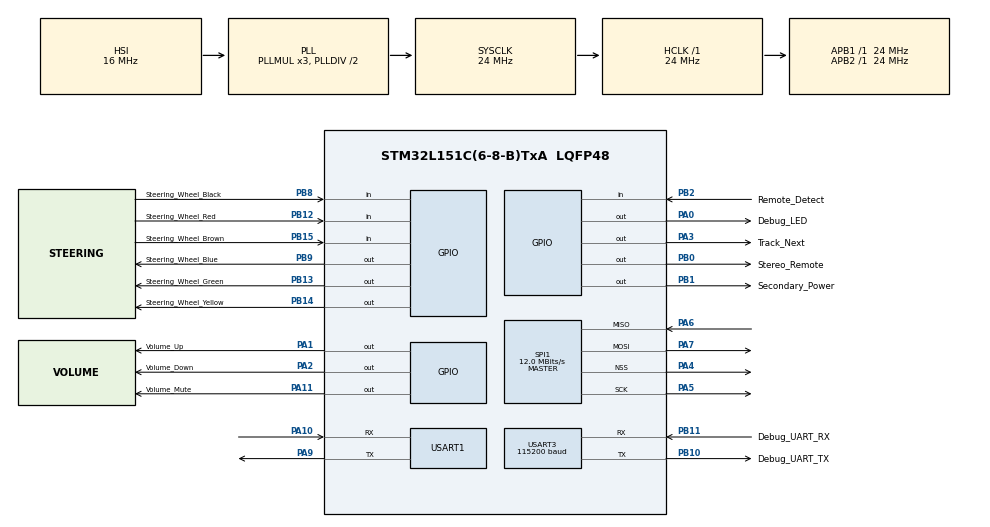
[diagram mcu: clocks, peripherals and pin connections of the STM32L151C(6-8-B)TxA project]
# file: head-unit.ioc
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Mcu.Family=STM32L1
Mcu.Name=STM32L151C(6-8-B)TxA
Mcu.Package=LQFP48
NVIC.PriorityGroup=NVIC_PRIORITYGROUP_4
PA0-WKUP1.GPIO_Label=Debug_LED
PA0-WKUP1.Signal=GPIO_Output
PA1.GPIO_Label=Volume_Up
PA1.Signal=GPIO_Output
PA10.Mode=Asynchronous
PA10.Signal=USART1_RX
PA11.GPIO_Label=Volume_Mute
PA11.Signal=GPIO_Output
PA13.GPIO_Label=Programmer_DIO
PA13.Signal=SYS_JTMS-SWDIO
PA14.GPIO_Label=Programmer_CLK
PA14.Signal=SYS_JTCK-SWCLK
PA2.GPIO_Label=Volume_Down
PA2.Signal=GPIO_Output
PA3.GPIO_Label=Track_Next
PA3.Signal=GPIO_Output
PA4.Mode=NSS_Signal_Hard_Output
PA4.Signal=SPI1_NSS
PA5.Mode=Full_Duplex_Master
PA5.Signal=SPI1_SCK
PA6.Mode=Full_Duplex_Master
PA6.Signal=SPI1_MISO
PA7.Mode=Full_Duplex_Master
PA7.Signal=SPI1_MOSI
PA9.Mode=Asynchronous
PA9.Signal=USART1_TX
PB0.GPIO_Label=Stereo_Remote
PB0.Signal=GPIO_Output
PB1.GPIO_Label=Secondary_Power
PB1.Signal=GPIO_Output
PB10.GPIO_Label=Debug_UART_TX
PB10.Mode=Asynchronous
PB10.Signal=USART3_TX
PB11.GPIO_Label=Debug_UART_RX
PB11.Mode=Asynchronous
PB11.Signal=USART3_RX
PB12.GPIO_Label=Steering_Wheel_Red
PB12.GPIO_PuPd=GPIO_PULLUP
PB12.Signal=GPIO_Input
PB13.GPIO_Label=Steering_Wheel_Green
PB13.Signal=GPIO_Output
PB14.GPIO_Label=Steering_Wheel_Yellow
PB14.Signal=GPIO_Output
PB15.GPIO_Label=Steering_Wheel_Brown
PB15.GPIO_PuPd=GPIO_PULLUP
PB15.Signal=GPIO_Input
PB2.GPIO_Label=Remote_Detect
PB2.Signal=GPIO_Input
PB8.GPIO_Label=Steering_Wheel_Black
PB8.GPIO_PuPd=GPIO_PULLUP
PB8.Signal=GPIO_Input
PB9.GPIO_Label=Steering_Wheel_Blue
PB9.Signal=GPIO_Output
ProjectManager.HeapSize=0x200
ProjectManager.StackSize=0x400
ProjectManager.TargetToolchain=STM32CubeIDE
RCC.48MHZClocksFreq_Value=24000000
RCC.AHBFreq_Value=24000000
RCC.APB1Freq_Value=24000000
RCC.APB1TimFreq_Value=24000000
RCC.APB2Freq_Value=24000000
RCC.APB2TimFreq_Value=24000000
RCC.HCLKFreq_Value=24000000
RCC.HSE_VALUE=24000000
RCC.HSI_VALUE=16000000
RCC.LSE_VALUE=32768
RCC.MSI_VALUE=2097000
RCC.SYSCLKFreq_VALUE=24000000
RCC.SYSCLKSource=RCC_SYSCLKSOURCE_PLLCLK
RCC.VCOOutputFreq_Value=48000000
SPI1.CalculateBaudRate=12.0 MBits/s
SPI1.Direction=SPI_DIRECTION_2LINES
SPI1.Mode=SPI_MODE_MASTER
SPI1.VirtualNSS=VM_NSSHARD
SPI1.VirtualType=VM_MASTER
USART1.VirtualMode=VM_ASYNC
USART3.BaudRate=115200
USART3.Mode=MODE_TX_RX
USART3.Parity=PARITY_NONE
USART3.VirtualMode=VM_ASYNC
board=custom

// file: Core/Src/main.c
/* USER CODE BEGIN Header */
/* USER CODE END Header */
#include "main.h"

/* USER CODE BEGIN Includes */
#include "debug.h"
#include "config.h"

/* USER CODE END Includes */

SPI_HandleTypeDef hspi1;

UART_HandleTypeDef huart1;
UART_HandleTypeDef huart3;

void SystemClock_Config(void);
static void MX_GPIO_Init(void);
static void MX_USART3_UART_Init(void);
static void MX_SPI1_Init(void);
static void MX_USART1_UART_Init(void);

int main(void)
{

  /* MCU Configuration--------------------------------------------------------*/

  /* Reset of all peripherals, Initializes the Flash interface and the Systick. */
  HAL_Init();

  /* Configure the system clock */
  SystemClock_Config();

  /* Initialize all configured peripherals */
  MX_GPIO_Init();
  MX_USART3_UART_Init();
  MX_SPI1_Init();
  MX_USART1_UART_Init();

  /* Infinite loop */
  while (1) {

  }
}

void SystemClock_Config(void)
{
  RCC_OscInitTypeDef RCC_OscInitStruct = {0};
  RCC_ClkInitTypeDef RCC_ClkInitStruct = {0};

  /** Configure the main internal regulator output voltage
  */
  __HAL_PWR_VOLTAGESCALING_CONFIG(PWR_REGULATOR_VOLTAGE_SCALE1);

  /** Initializes the RCC Oscillators according to the specified parameters
  * in the RCC_OscInitTypeDef structure.
  */
  RCC_OscInitStruct.OscillatorType = RCC_OSCILLATORTYPE_HSI;
  RCC_OscInitStruct.HSIState = RCC_HSI_ON;
  RCC_OscInitStruct.HSICalibrationValue = RCC_HSICALIBRATION_DEFAULT;
  RCC_OscInitStruct.PLL.PLLState = RCC_PLL_ON;
  RCC_OscInitStruct.PLL.PLLSource = RCC_PLLSOURCE_HSI;
  RCC_OscInitStruct.PLL.PLLMUL = RCC_PLL_MUL3;
  RCC_OscInitStruct.PLL.PLLDIV = RCC_PLL_DIV2;
  if (HAL_RCC_OscConfig(&RCC_OscInitStruct) != HAL_OK)
  {
    Error_Handler();
  }

  /** Initializes the CPU, AHB and APB buses clocks
  */
  RCC_ClkInitStruct.ClockType = RCC_CLOCKTYPE_HCLK|RCC_CLOCKTYPE_SYSCLK
                              |RCC_CLOCKTYPE_PCLK1|RCC_CLOCKTYPE_PCLK2;
  RCC_ClkInitStruct.SYSCLKSource = RCC_SYSCLKSOURCE_PLLCLK;
  RCC_ClkInitStruct.AHBCLKDivider = RCC_SYSCLK_DIV1;
  RCC_ClkInitStruct.APB1CLKDivider = RCC_HCLK_DIV1;
  RCC_ClkInitStruct.APB2CLKDivider = RCC_HCLK_DIV1;

  if (HAL_RCC_ClockConfig(&RCC_ClkInitStruct, FLASH_LATENCY_1) != HAL_OK)
  {
    Error_Handler();
  }
}

static void MX_SPI1_Init(void)
{

  /* SPI1 parameter configuration*/
  hspi1.Instance = SPI1;
  hspi1.Init.Mode = SPI_MODE_MASTER;
  hspi1.Init.Direction = SPI_DIRECTION_2LINES;
  hspi1.Init.DataSize = SPI_DATASIZE_8BIT;
  hspi1.Init.CLKPolarity = SPI_POLARITY_LOW;
  hspi1.Init.CLKPhase = SPI_PHASE_1EDGE;
  hspi1.Init.NSS = SPI_NSS_HARD_OUTPUT;
  hspi1.Init.BaudRatePrescaler = SPI_BAUDRATEPRESCALER_2;
  hspi1.Init.FirstBit = SPI_FIRSTBIT_MSB;
  hspi1.Init.TIMode = SPI_TIMODE_DISABLE;
  hspi1.Init.CRCCalculation = SPI_CRCCALCULATION_DISABLE;
  hspi1.Init.CRCPolynomial = 10;
  if (HAL_SPI_Init(&hspi1) != HAL_OK)
  {
    Error_Handler();
  }

}

static void MX_USART1_UART_Init(void)
{

  huart1.Instance = USART1;
  huart1.Init.BaudRate = 115200;
  huart1.Init.WordLength = UART_WORDLENGTH_8B;
  huart1.Init.StopBits = UART_STOPBITS_1;
  huart1.Init.Parity = UART_PARITY_NONE;
  huart1.Init.Mode = UART_MODE_TX_RX;
  huart1.Init.HwFlowCtl = UART_HWCONTROL_NONE;
  huart1.Init.OverSampling = UART_OVERSAMPLING_16;
  if (HAL_UART_Init(&huart1) != HAL_OK)
  {
    Error_Handler();
  }

}

static void MX_USART3_UART_Init(void)
{

  huart3.Instance = USART3;
  huart3.Init.BaudRate = 115200;
  huart3.Init.WordLength = UART_WORDLENGTH_8B;
  huart3.Init.StopBits = UART_STOPBITS_1;
  huart3.Init.Parity = UART_PARITY_NONE;
  huart3.Init.Mode = UART_MODE_TX_RX;
  huart3.Init.HwFlowCtl = UART_HWCONTROL_NONE;
  huart3.Init.OverSampling = UART_OVERSAMPLING_16;
  if (HAL_UART_Init(&huart3) != HAL_OK)
  {
    Error_Handler();
  }

}

static void MX_GPIO_Init(void)
{
  GPIO_InitTypeDef GPIO_InitStruct = {0};

  /* GPIO Ports Clock Enable */
  __HAL_RCC_GPIOC_CLK_ENABLE();
  __HAL_RCC_GPIOH_CLK_ENABLE();
  __HAL_RCC_GPIOA_CLK_ENABLE();
  __HAL_RCC_GPIOB_CLK_ENABLE();

  /*Configure GPIO pin Output Level */
  HAL_GPIO_WritePin(GPIOA, Debug_LED_Pin|Volume_Up_Pin|Volume_Down_Pin|Track_Next_Pin
                          |Volume_Mute_Pin, GPIO_PIN_RESET);

  /*Configure GPIO pin Output Level */
  HAL_GPIO_WritePin(GPIOB, Stereo_Remote_Pin|Secondary_Power_Pin|Steering_Wheel_Green_Pin|Steering_Wheel_Yellow_Pin
                          |Steering_Wheel_Blue_Pin, GPIO_PIN_RESET);

  /*Configure GPIO pins : PC13 PC14 PC15 */
  GPIO_InitStruct.Pin = GPIO_PIN_13|GPIO_PIN_14|GPIO_PIN_15;
  GPIO_InitStruct.Mode = GPIO_MODE_ANALOG;
  GPIO_InitStruct.Pull = GPIO_NOPULL;
  HAL_GPIO_Init(GPIOC, &GPIO_InitStruct);

  /*Configure GPIO pins : PH0 PH1 */
  GPIO_InitStruct.Pin = GPIO_PIN_0|GPIO_PIN_1;
  GPIO_InitStruct.Mode = GPIO_MODE_ANALOG;
  GPIO_InitStruct.Pull = GPIO_NOPULL;
  HAL_GPIO_Init(GPIOH, &GPIO_InitStruct);

  /*Configure GPIO pins : Debug_LED_Pin Volume_Up_Pin Volume_Down_Pin Track_Next_Pin
                           Volume_Mute_Pin */
  GPIO_InitStruct.Pin = Debug_LED_Pin|Volume_Up_Pin|Volume_Down_Pin|Track_Next_Pin
                          |Volume_Mute_Pin;
  GPIO_InitStruct.Mode = GPIO_MODE_OUTPUT_PP;
  GPIO_InitStruct.Pull = GPIO_NOPULL;
  GPIO_InitStruct.Speed = GPIO_SPEED_FREQ_LOW;
  HAL_GPIO_Init(GPIOA, &GPIO_InitStruct);

  /*Configure GPIO pins : Stereo_Remote_Pin Secondary_Power_Pin Steering_Wheel_Green_Pin Steering_Wheel_Yellow_Pin
                           Steering_Wheel_Blue_Pin */
  GPIO_InitStruct.Pin = Stereo_Remote_Pin|Secondary_Power_Pin|Steering_Wheel_Green_Pin|Steering_Wheel_Yellow_Pin
                          |Steering_Wheel_Blue_Pin;
  GPIO_InitStruct.Mode = GPIO_MODE_OUTPUT_PP;
  GPIO_InitStruct.Pull = GPIO_NOPULL;
  GPIO_InitStruct.Speed = GPIO_SPEED_FREQ_LOW;
  HAL_GPIO_Init(GPIOB, &GPIO_InitStruct);

  /*Configure GPIO pin : Remote_Detect_Pin */
  GPIO_InitStruct.Pin = Remote_Detect_Pin;
  GPIO_InitStruct.Mode = GPIO_MODE_INPUT;
  GPIO_InitStruct.Pull = GPIO_NOPULL;
  HAL_GPIO_Init(Remote_Detect_GPIO_Port, &GPIO_InitStruct);

  /*Configure GPIO pins : Steering_Wheel_Red_Pin Steering_Wheel_Brown_Pin Steering_Wheel_Black_Pin */
  GPIO_InitStruct.Pin = Steering_Wheel_Red_Pin|Steering_Wheel_Brown_Pin|Steering_Wheel_Black_Pin;
  GPIO_InitStruct.Mode = GPIO_MODE_INPUT;
  GPIO_InitStruct.Pull = GPIO_PULLUP;
  HAL_GPIO_Init(GPIOB, &GPIO_InitStruct);

  /*Configure GPIO pins : PA8 PA12 PA15 */
  GPIO_InitStruct.Pin = GPIO_PIN_8|GPIO_PIN_12|GPIO_PIN_15;
  GPIO_InitStruct.Mode = GPIO_MODE_ANALOG;
  GPIO_InitStruct.Pull = GPIO_NOPULL;
  HAL_GPIO_Init(GPIOA, &GPIO_InitStruct);

  /*Configure GPIO pins : PB3 PB4 PB5 PB6
                           PB7 */
  GPIO_InitStruct.Pin = GPIO_PIN_3|GPIO_PIN_4|GPIO_PIN_5|GPIO_PIN_6
                          |GPIO_PIN_7;
  GPIO_InitStruct.Mode = GPIO_MODE_ANALOG;
  GPIO_InitStruct.Pull = GPIO_NOPULL;
  HAL_GPIO_Init(GPIOB, &GPIO_InitStruct);

}

void Error_Handler(void)
{
  __disable_irq();
  while (1) {
  }
}
